# R40 register map
Vendor: Allwinner; Series: R40; File version: 0.1
CPU: CA7 0, little endian, MPU, FPU, double-precision FPU, 0 interrupt priority bits
Registers are 32-bit, read-write, reset 0x0 unless marked. A register's access mark holds for its fields unless they carry their own. Offsets are from the block's base; [hi:lo] are bit positions; 'fields as' and 'values as' point back to an identical list.

## AC97
Base 0x01C21400
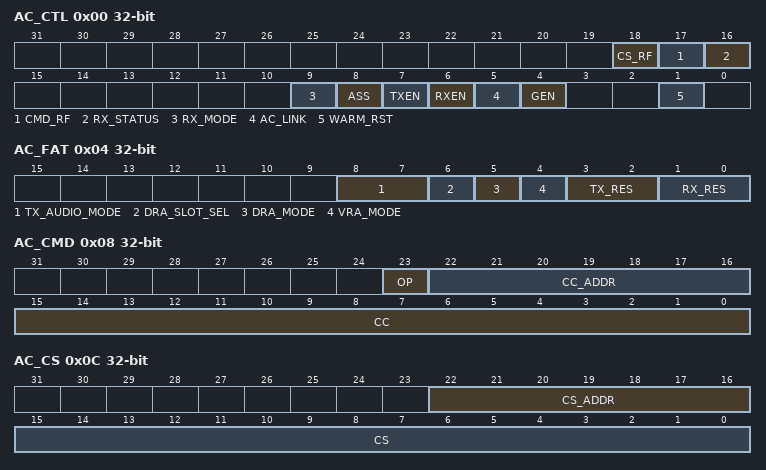
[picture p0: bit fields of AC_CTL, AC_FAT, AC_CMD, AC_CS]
0x00 AC_CTL — AC97 Control Register
  [18] CS_RF ro — CODEC Status Register FLAG 0: Empty 1: Full
    0=Empty; 1=Full
  [17] CMD_RF ro — CMD Register FLAG 0: Empty 1: Full
    0=Empty; 1=Full
  [16] RX_STATUS ro — RX Transfer Status 0: PCM IN 1: MIC IN
    0=PCM (PCM IN); 1=MIC (MIC IN)
  [9] RX_MODE — RX MODE 0: PCM IN 1: MIC IN This bit indicates which mode will be selected when PCM IN and MIC IN slots are available simultaneously
    0=PCM (PCM IN); 1=MIC (MIC IN This bit indicates which mode will be selected when PCM IN and MIC IN slots are available simultaneously)
  [8] ASS — Audio sample select with TX FIFO under run 0: Sending 0 (invalid frame) 1: Sending the last audio (valid frame)
    0=Sending 0 (invalid frame); 1=Sending the last audio (valid frame)
  [7] TXEN — 0: Disable 1: Enable This bit is controlled by , we can enable this bit, only after the globe enable bit is enabled.
    0=Disable; 1=Enable This bit is controlled by , we can enable this bit, only after the globe enable bit is enabled
  [6] RXEN — 0: Disable 1: Enable This bit is controlled by , we can enable this bit, only after the globe enable bit is enabled.
    values as TXEN
  [5] AC_LINK — AC-link EN 0: Disable 1: Enable(SYNC signal transfer to Codec) This bit is controlled by , we can enable this bit, only after the globe enable is enabled.
    0=Disable; 1=Enable_openingparen_SYNC (Enable(SYNC signal transfer to Codec) This bit is controlled by , we can enable this bit, only after the globe enable is enabled.)
  [4] GEN — Globe Enable A disable on this bit overrides any other block or channel enables. 0: Disable 1: Enable
    0=Disable; 1=Enable
  [1] WARM_RST write-1-clears — Warm reset 0: Normal 1: Wake up codec from power down Note: Self clear to `0`
    0=Normal; 1=Wake up codec from power down Note: Self clear to `0`
0x04 AC_FAT — AC97 Format Register
  [8:7] TX_AUDIO_MODE — TX audio mode 00: 2-channel(PCM l/r main) 01: 6-channel(PCM l/r main, l/r surround, center, AFE) 10: Reserved 11: Reserved
    0=_2_minus_channel_openingparen_PCM (2-channel(PCM l/r main)); 1=_6_minus_channel_openingparen_PCM (6-channel(PCM l/r main, l/r surround, center, AFE))
  [6] DRA_SLOT_SEL — DRA additional slots select (available in 2-channel mode) 0: Select slot 10, slot 11 1: Select slot 7, slot 8
    0=Select slot 10, slot 11; 1=Select slot 7, slot 8
  [5] DRA_MODE — DRA mode 0: Non-DRA 1: DRA
    0=non_DRA; 1=DRA
  [4] VRA_MODE — VRA Mode 0: Non-VRA 1: VRA
    0=non_VRA; 1=VRA
  [3:2] TX_RES — TX Audio data resolution 00: 16-bit 01: 18-bit 10: 20-bit 11: Reserved
    0=_16_bit; 1=_18_bit; 2=_20_bit
  [1:0] RX_RES — RX Audio data resolution 00: 16-bit 01: 18-bit 10: 20-bit 11: Reserved
    0=_16_bit; 1=_18_bit; 2=_20_bit
0x08 AC_CMD — AC97 Command Register
  [23] OP — Read enable 0: Command write 1: Status read
    0=Command write; 1=Status read
  [22:16] CC_ADDR — Codec command address
  [15:0] CC — Codec command data
0x0C AC_CS — AC97 Codec Status Register
  [22:16] CS_ADDR ro — Codec status address
  [15:0] CS ro — Codec status data
0x10 AC_RXFIFO
  [31:0] RX_DATA ro — Host can get one sample by reading this register. If in the PCM IN mode, the left channel sample data is first and then the right channel sample
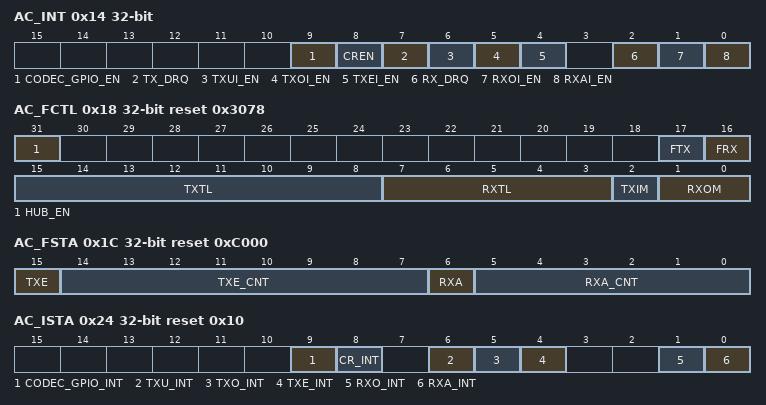
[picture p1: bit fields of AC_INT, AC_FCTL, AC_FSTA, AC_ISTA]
0x14 AC_INT — AC97 Interrupt Control Register
  [all] fields
    0=Disable; 1=Enable
  [9] CODEC_GPIO_EN — Codec GPIO interrupt Enable 0: Disable 1: Enable
  [8] CREN — Codec Ready interrupt Enable 0: Disable 1: Enable
  [7] TX_DRQ — TX FIFO Empty DRQ Enable 0: Disable 1: Enable
  [6] TXUI_EN — TX FIFO Under run Interrupt Enable 0: Disable 1: Enable
  [5] TXOI_EN — TX FIFO Overrun Interrupt Enable 0: Disable 1: Enable
  [4] TXEI_EN — TX FIFO Empty Interrupt Enable 0: Disable 1: Enable
  [2] RX_DRQ — RX FIFO Data Available DRQ Enable When set to `1`, RX FIFO DMA Request is asserted if data is available in RX FIFO. 0: Disable 1: Enable
  [1] RXOI_EN — RX FIFO Overrun Interrupt Enable 0: Disable 1: Enable
  [0] RXAI_EN — RX FIFO Data Available Interrupt Enable 0: Disable 1: Enable
0x18 AC_FCTL reset 0x3078 — AC97 FIFO Control Register
  [31] HUB_EN — Audio hub enable 0: Disable 1: Enable
    0=Disable; 1=Enable
  [17] FTX write-1-clears — Write `1` to flush TX FIFO, self clear to `0`
  [16] FRX write-1-clears — Write `1` to flush RX FIFO, self clear to `0`
  [15:8] TXTL — TX FIFO empty Trigger Level Interrupt and DMA request trigger level for TX FIFO normal condition Trigger Level = TXTL
  [7:3] RXTL — RX FIFO Trigger Level Interrupt and DMA request trigger level for RX FIFO normal condition Trigger Level =RXTL + 1
  [2] TXIM — TX FIFO Input Mode(Mode0, 1) 0: Valid data at the MSB of AC_TXFIFO register 1: Valid data at the LSB of AC_TXFIFO register Example for 18-bit transmitted audio sample: Mode 0: FIFO_I*19:0+ = ,TXFIFO*31:14+, 2`h0- Mode 1: FIFO_I*19:0+ = ,TXFIFO*17:0+, 2`h0-
    0=Valid data at the MSB of AC_TXFIFO register; 1=Valid data at the LSB of AC_TXFIFO register Example for 18-bit transmitted audio sample: Mode 0: FIFO_I*19:0+ = ,TXFIFO*31:14+, 2`h0- Mode 1: FIFO_I*19:0+ = ,TXFIFO*17:0+, 2`h0-
  [1:0] RXOM — RX FIFO Output Mode(Mode 0,1,2,3) 00: Expanding `0` at LSB of AC_RXFIFO register 01: Expanding received sample sign bit at MSB of AC_RXFIFO register 10: Truncating received samples at high half-word of AC_RXFIFO register and low half-word of AC_FIFO register is filled by `0` 11: Truncating received samples at low half-word of AC_RXFIFO register and high half-word of AC_FIFO register is expanded by its sigh bit Example for 18-bit received audio sample: Mode0: RXFIFO*31:0+ = ,FIFO_O*19:2+, 14`h0- Mode 1: RXFIFO[31:0+ = ,14`FIFO_O*19+, FIFO_O*19:2+- Mode 2: RXFIFO*31:0+ = ,FIFO_O*19:4+, 16`h0- Mode 3: RXFIFO*31:0+ = ,16`FIFO_O*19+, FIFO_O*19:4+-
    0=Expanding `0` at LSB of AC_RXFIFO register; 1=Expanding received sample sign bit at MSB of AC_RXFIFO register; 2=Truncating received samples at high half-word of AC_RXFIFO register and low half-word of AC_FIFO register is filled by `0`; 3=Truncating received samples at low half-word of AC_RXFIFO register and high half-word of AC_FIFO register is expanded by its sigh bit Example for 18-bit received audio sample: Mode0: RXFIFO*31:0+ = ,FIFO_O*19:2+, 14`h0- Mode 1: RXFIFO[31:0+ = ,14`FIFO_O*19+, FIFO_O*19:2+- Mode 2: RXFIFO*31:0+ = ,FIFO_O*19:4+, 16`h0- Mode 3: RXFIFO*31:0+ = ,16`FIFO_O*19+, FIFO_O*19:4+-
0x1C AC_FSTA reset 0xC000 — AC97 FIFO Status Register
  [15] TXE ro — TX FIFO Empty 0: No room for new sample in TX FIFO 1: More than one room for new sample in TX FIFO ( >=1 word )
    0=No room for new sample in TX FIFO; 1=More than one room for new sample in TX FIFO ( >=1 word )
  [14:7] TXE_CNT ro — TX FIFO Empty Space Word counter
  [6] RXA ro — RX FIFO Available 0: No available data in RX FIFO 1: More than one sample in RX FIFO ( >=1 word )
    0=No available data in RX FIFO; 1=More than one sample in RX FIFO ( >=1 word )
  [5:0] RXA_CNT ro — RX FIFO Available Sample Word counter
0x20 AC_TXFIFO
  [31:0] TX_DATA wo — Transmitting left, right channel sample data should be written this register one by one. The left channel sample data is first and then the right channel sample.
0x24 AC_ISTA reset 0x10 — AC97 Interrupt Status Register
  [9] CODEC_GPIO_INT write-1-clears — Codec GPIO interrupt 0: No pending IRQ 1: Codec GPIO interrupt Write `1` to clear this interrupt
    0=No pending IRQ; 1=Codec GPIO interrupt Write `1` to clear this interrupt
  [8] CR_INT write-1-clears — Codec Ready pending Interrupt 0: No pending IRQ 1: Codec Ready Pending Interrupt Write `1` to clear this interrupt
    0=No pending IRQ; 1=Codec Ready Pending Interrupt Write `1` to clear this interrupt
  [6] TXU_INT write-1-clears — TX FIFO Under run Pending Interrupt 0: No pending IRQ 1: FIFO Under run Pending Interrupt Write `1` to clear this interrupt
    0=No pending IRQ; 1=FIFO (FIFO Under run Pending Interrupt Write `1` to clear this interrupt)
  [5] TXO_INT write-1-clears — TX FIFO Overrun Pending Interrupt 0: No Pending IRQ 1: FIFO Overrun Pending Interrupt Write `1` to clear this interrupt
    0=No Pending IRQ; 1=FIFO (FIFO Overrun Pending Interrupt Write `1` to clear this interrupt)
  [4] TXE_INT write-1-clears — TX FIFO Empty Pending Interrupt 0: No Pending IRQ 1: FIFO Empty Pending Interrupt Write `1` to clear this interrupt or automatically clear if interrupt condition fails.
    0=No Pending IRQ; 1=FIFO (FIFO Empty Pending Interrupt Write `1` to clear this interrupt or automatically clear if interrupt condition fails.)
  [1] RXO_INT write-1-clears — RX FIFO Overrun Pending Interrupt 0: FIFO Overrun Pending Write `1` to clear this interrupt.
    0=FIFO (FIFO Overrun Pending Write `1` to clear this interrupt.)
  [0] RXA_INT write-1-clears — RX FIFO Available Pending Interrupt 0: No Pending IRQ 1: Data Available Pending IRQ Write `1` to clear this interrupt or automatically clear if interrupt condition fails.
    0=No Pending IRQ; 1=Data Available Pending IRQ Write `1` to clear this interrupt or automatically clear if interrupt condition fails
0x28 AC_TX_CNT — AC97 TX Counter Register
  [31:0] TX_CNT — TX Sample counter The audio sample number of writing into TX FIFO. When one sample is written by DMA or by host IO, the TX sample counter register increases by one. The TX Counter register can be set to any initial value at any time. After been updated by the initial value, the counter register should count on base of this value.
0x2C AC_RX_CNT — AC97 RX Counter Register
  [31:0] RX_CNT — RX Sample counter The audio sample number of writing into RX FIFO. When one sample is written by Codec, the RX sample counter register increases by one. The RX Counter register can be set to any initial value at any time. After been updated by the initial value, the counter register should count on base of this value.
